VERSION ""

NS_ :

BS_:

BU_: TheNode
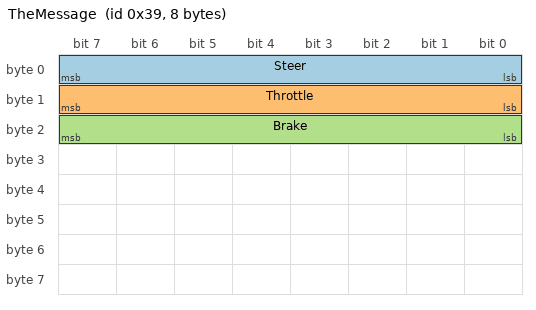
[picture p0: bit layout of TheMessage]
BO_ 57 TheMessage: 8 Vector__XXX
 SG_ Steer : 0|8@1- (1,0) [-127|127] "" Vector__XXX
 SG_ Throttle : 8|8@1+ (1,0) [0|100] "" Vector__XXX
 SG_ Brake : 16|8@1+ (1,0) [0|100] "" Vector__XXX

CM_ BU_ TheNode "TheNodeComment";
BA_DEF_ SG_  "TheSignalStringAttribute" STRING ;
BA_DEF_  "TheNetworkAttribute" INT 0 100;
BA_DEF_ BO_  "TheHexAttribute" HEX 0 8;
BA_DEF_ BO_  "TheFloatAttribute" FLOAT 5 87;
BA_DEF_ BU_  "TheNodeAttribute" INT 50 150;
BA_DEF_ BU_  "NodeLayerModules" STRING ;
BA_DEF_ BO_  "GenMsgILSupport" ENUM  "No","Yes";
BA_DEF_  "NmBaseAddress" HEX 1024 1087;
BA_DEF_  "BusType" STRING ;
BA_DEF_ BO_  "GenMsgCycleTime" INT 0 50000;
BA_DEF_ BO_  "GenMsgSendType" ENUM  "Cyclic","NotUsed","NotUsed","NotUsed","NotUsed","NotUsed","NotUsed","IfActive","NoMsgSendType","NotUsed","vector_leerstring";
BA_DEF_ SG_  "GenSigSendType" ENUM  "Cyclic","OnWrite","OnWriteWithRepetition","OnChange","OnChangeWithRepetition","IfActive","IfActiveWithRepetition","NoSigSendType","NotUsed","NotUsed","NotUsed","NotUsed","NotUsed";
BA_DEF_DEF_  "TheSignalStringAttribute" "";
BA_DEF_DEF_  "TheNetworkAttribute" 50;
BA_DEF_DEF_  "TheHexAttribute" 4;
BA_DEF_DEF_  "TheFloatAttribute" 55;
BA_DEF_DEF_  "TheNodeAttribute" 100;
BA_DEF_DEF_  "NodeLayerModules" "CANoeILNLVector.dll";
BA_DEF_DEF_  "GenMsgILSupport" "Yes";
BA_DEF_DEF_  "NmBaseAddress" 1024;
BA_DEF_DEF_  "BusType" "";
BA_DEF_DEF_  "GenMsgCycleTime" 0;
BA_DEF_DEF_  "GenMsgSendType" "NoMsgSendType";
BA_DEF_DEF_  "GenSigSendType" "Cyclic";
BA_ "TheNetworkAttribute" 51;
BA_ "BusType" "CAN";
BA_ "TheNodeAttribute" BU_ TheNode 99;
BA_ "TheFloatAttribute" BO_ 57 58.7;
BA_ "TheHexAttribute" BO_ 57 5;
BA_ "GenMsgSendType" BO_ 57 0;
BA_ "GenMsgCycleTime" BO_ 57 1000;
BA_ "TheSignalStringAttribute" SG_ 57 TheSignal "TestString";
BA_ "GenSigSendType" SG_ 57 TheSignal 1;
